# NUC123AN_v1 register map
File version: 1.0
Registers are 32-bit, read-write, reset 0x0 unless marked. A register's access mark holds for its fields unless they carry their own. Offsets are from the block's base; [hi:lo] are bit positions; {n}, {i} and the like mark numbered series.

## PS2 — PS2 Register Map
Base 0x40100000
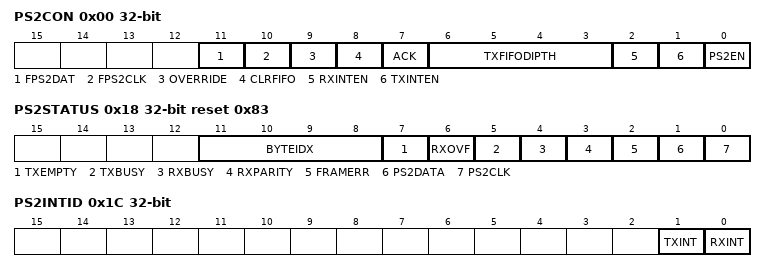
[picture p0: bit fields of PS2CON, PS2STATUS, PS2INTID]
0x00 PS2CON — PS/2 Control Register
  [11] FPS2DAT — Force PS2DATA Line. It forces PS2DATA high or low regardless of the internal state of the device controller if OVERRIDE is set to high.
    0=Force PS2DATA low; 1=Force PS2DATA high
  [10] FPS2CLK — Force PS2CLK Line. It forces PS2CLK line high or low regardless of the internal state of the device controller if OVERRIDE is set to high.
    0=Force PS2CLK line low; 1=Force PS2CLK line high
  [9] OVERRIDE — Software Override PS/2 CLK/DATA Pin State
    0=PS2CLK and PS2DATA pins are controlled by internal state machine; 1=PS2CLK and PS2DATA pins are controlled by software
  [8] CLRFIFO — Clear TX FIFO. Write 1 to this bit to terminate device to host transmission. The TXEMPTY bit in PS2STATUS bit will be set to 1 and pointer BYTEIDEX is reset to 0 regardless there is residue data in buffer or not. The buffer content is not been cleared.
    0=Not active; 1=Clear FIFO
  [7] ACK — Acknowledge Enable
    0=Always sends acknowledge to host at 12th clock for host to device communication; 1=If parity error or stop bit is not received correctly, acknowledge bit will not be sent to host at 12th clock
  [6:3] TXFIFODIPTH — Transmit Data FIFO Depth. There is 16-byte buffer for data transmit. Software can define the FIFO depth from 1 to 16 bytes depending on the application.
    0=1 byte; 1=2 bytes; 14=15 bytes; 15=16 bytes
  [2] RXINTEN — Enable Receive Interrupt
    0=Data receive complete interrupt Disabled; 1=Data receive complete interrupt Enabled
  [1] TXINTEN — Enable Transmit Interrupt
    0=Data transmit complete interrupt Disabled; 1=Data transmit complete interrupt Enabled
  [0] PS2EN — Enable PS/2 Device. Enable PS/2 device controller.
    0=Disabled; 1=Enabled
{0x4+4i} PS2TXDATA{i} (i=0..3) — PS/2 Transmit Data Register {i}
  [31:0] PS2TXDATAx — Transmit data. Write data to this register starts device to host communication if bus is in IDLE state. Software must enable PS2EN before writing data to TX buffer.
0x14 PS2RXDATA ro — PS/2 Receive Data Register
  [7:0] PS2RXDATA — Received Data. For host to device communication, after acknowledge bit is sent, the received data is copied from receive shift register to PS2RXDATA register. CPU must read this register before next byte reception complete; otherwise, the data will be overwritten and RXOVF bit in PS2STATUS[6] will be set to 1.
0x18 PS2STATUS reset 0x83
  [11:8] BYTEIDX — Byte Index
  [7] TXEMPTY — TX FIFO Empty. When software writes any data to PS2TXDATA0-3 the TXEMPTY bit is cleared to 0 immediately if PS2EN is enabled. When transmitted data byte number is equal to FIFODEPTH then TXEMPTY bit is set to 1. Read only bit.
    0=There is data to be transmitted; 1=FIFO is empty
  [6] RXOVF — RX Buffer Overwrite. Write 1 to clear this bit.
    0=No overwrite; 1=Data in PS2RXDATA register is overwritten by new received data
  [5] TXBUSY — Transmit Busy. This bit indicates that the PS/2 device is currently sending data. Read only bit.
    0=Idle; 1=Currently sending data
  [4] RXBUSY — Receive Busy. This bit indicates that the PS/2 device is currently receiving data. Read only bit.
    0=Idle; 1=Currently receiving data
  [3] RXPARITY — Received Parity. This bit reflects the parity bit for the last received data byte (odd parity). Read only bit.
  [2] FRAMERR — Frame Error. For host to device communication, if STOP bit (logic 1) is not received it is a frame error. If frame error occurs, DATA line may keep at low state after 12th clock. At this moment, software overrides PS2CLK to send clock till PS2DATA release to high state. After that, device sends a "Resend" command to host. Write 1 to clear this bit.
    0=No frame error; 1=Frame error occurred
  [1] PS2DATA — DATA Pin State. This bit reflects the status of the PS2DATA line after synchronizing and sampling.
  [0] PS2CLK — CLK Pin State. This bit reflects the status of the PS2CLK line after synchronizing.
0x1C PS2INTID — PS/2 Interrupt Identification Register
  [1] TXINT — Transmit Interrupt. This bit is set to 1 after STOP bit is transmitted. Interrupt occurs if TXINTEN bit is set to 1. Write 1 to clear this bit to 0.
    0=No interrupt; 1=Transmit interrupt occurs
  [0] RXINT — Receive Interrupt. This bit is set to 1 when acknowledge bit is sent for Host to device communication. Interrupt occurs if RXINTEN bit is set to 1. Write 1 to clear this bit to 0.
    0=No interrupt; 1=Receive interrupt occurs
